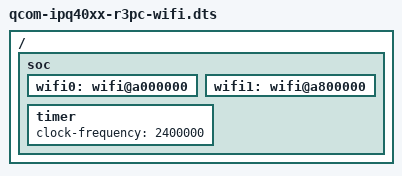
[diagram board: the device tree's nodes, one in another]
/* Copyright (c) 2014, The Linux Foundation. All rights reserved.
 *
 * This program is free software; you can redistribute it and/or modify
 * it under the terms of the GNU General Public License version 2 and
 * only version 2 as published by the Free Software Foundation.
 *
 * This program is distributed in the hope that it will be useful,
 * but WITHOUT ANY WARRANTY; without even the implied warranty of
 * MERCHANTABILITY or FITNESS FOR A PARTICULAR PURPOSE.  See the
 * GNU General Public License for more details.
 */

#include "qcom-ipq40xx-r3pc.dts"

/ {
	soc {
		wifi0: wifi@a000000 {
			status = "ok";
		};
		wifi1: wifi@a800000 {
			status = "ok";
		};
		timer {
			clock-frequency = <2400000>;
		};
	};
};
